# LPC54102_cm4 register map
Vendor: nxp.com; File version: 1.0
LPC54102J256BD64,LPC54102J256UK49,LPC54102J512BD64,LPC54102J512UK49
CPU: CM4 r0p1, little endian, MPU, FPU, VTOR, 3 interrupt priority bits
Registers are 32-bit, read-write, reset 0x0 unless marked. A register's access mark holds for its fields unless they carry their own. Offsets are from the block's base; lines under a group give offsets from that group; [hi:lo] are bit positions; {n}, {i} and the like mark numbered series; 'fields as' and 'values as' point back to an identical list; <NAME> marks a mode.

## Memory map
0x1C000000 GPIO size 0x2488 — LPC5410x General Purpose I/O (GPIO)
0x1C004000 DMA0 size 0x55C — LPC5410x DMA controller
0x1C010000 CRC_ENGINE size 0xC — LPC5410x CRC engine
0x1C018000 SCT0 size 0x540 — SCTimer/PWM (SCT)
0x1C02C000 MAILBOX size 0xFC — LPC5410x Mailbox
0x1C034000 ADC0 size 0x74 — LPC5410x 12-bit ADC controller (ADC)
0x1C038000 VFIFO size 0x211C — System FIFO for Serial Peripherals
0x40000000 SYSCON size 0x2C048 — System configuration
0x40004000 CTIMER2 size 0x78 — LPC5410x Standard counter/timers (CTIMER0 to 4)
0x40008000 CTIMER3 size 0x78 — LPC5410x Standard counter/timers (CTIMER0 to 4)
0x4000C000 CTIMER4 size 0x78 — LPC5410x Standard counter/timers (CTIMER0 to 4)
0x40010000 GINT0 size 0x48 — LPC5410x Group GPIO input interrupt (GINT0/1)
0x40014000 GINT1 size 0x48 — LPC5410x Group GPIO input interrupt (GINT0/1)
0x40018000 PINT size 0x34 — LPC5410x Pin interrupt and pattern match (PINT)
0x4001C000 IOCON size 0x100 — LPC5410x I/O pin configuration (IOCON)
0x40020000 UTICK0 size 0x20 — LPC5410x Micro-tick Timer (UTICK)
0x40038000 WWDT size 0x1C — LPC5410x Windowed Watchdog Timer (WWDT)
0x4003C000 RTC size 0x10 — LPC5410x Real-Time Clock (RTC)
0x40050000 INPUTMUX size 0x168 — LPC5410x Input multiplexing (INPUT MUX)
0x40070000 RIT size 0x20 — Repetitive Interrupt Timer
0x40074000 MRT0 size 0xFC — LPC5410x Multi-Rate Timer (MRT)
0x40080000 ASYNC_SYSCON size 0x34 — LPC5410x Asynchronous system configuration (ASYNC_SYSCON)
0x40084000 USART0 size 0x30 — USART
0x40088000 USART1 size 0x30 — USART
0x4008C000 USART2 size 0x30 — USART
0x40090000 USART3 size 0x30 — USART
0x40094000 I2C0 size 0x84 — I2C-bus interface 0
0x40098000 I2C1 size 0x84 — I2C-bus interface 0
0x4009C000 I2C2 size 0x84 — I2C-bus interface 0
0x400A4000 SPI0 size 0x2C — SPI
0x400A8000 SPI1 size 0x2C — SPI
0x400B4000 CTIMER0 size 0x78 — LPC5410x Standard counter/timers (CTIMER0 to 4)
0x400B8000 CTIMER1 size 0x78 — LPC5410x Standard counter/timers (CTIMER0 to 4)
0xE0000000 ITM size 0x1000 — Instrumentation Trace Macrocell Registers
0xE000E000 SystemControl size 0xD40 — System Control Block
0xE000E010 SysTick size 0x10 — System timer
0xE000E100 NVIC size 0xE04 — Nested Vectored Interrupt Controller

## Interrupts
0 WDT (WWDT)
3 DMA0
4 GINT0
5 PIN_INT0 (PINT)
6 PIN_INT1 (PINT)
7 PIN_INT2 (PINT)
8 PIN_INT3 (PINT)
9 UTICK0
10 MRT0
11 CTIMER0
12 CTIMER1
13 CTIMER2
14 CTIMER3
15 CTIMER4
16 SCT0
17 USART0
18 USART1
19 USART2
20 USART3
21 I2C0
22 I2C1
23 I2C2
24 SPI0
25 SPI1
26 ADC0_SEQA (ADC0)
27 ADC0_SEQB (ADC0)
28 ADC0_THCMP (ADC0)
29 RTC
31 MAILBOX
32 GINT1
33 PIN_INT4 (PINT)
34 PIN_INT5 (PINT)
35 PIN_INT6 (PINT)
36 PIN_INT7 (PINT)
40 RIT

## CRC_ENGINE — LPC5410x CRC engine
Base 0x1C010000
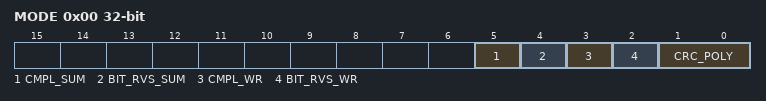
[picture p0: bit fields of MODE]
0x00 MODE — CRC mode register
  [5] CMPL_SUM — CRC sum complement: 1 = 1's complement for CRC_SUM 0 = No 1's complement for CRC_SUM
  [4] BIT_RVS_SUM — CRC sum bit order: 1 = Bit order reverse for CRC_SUM 0 = No bit order reverse for CRC_SUM
  [3] CMPL_WR — Data complement: 1 = 1's complement for CRC_WR_DATA 0 = No 1's complement for CRC_WR_DATA
  [2] BIT_RVS_WR — Data bit order: 1 = Bit order reverse for CRC_WR_DATA (per byte) 0 = No bit order reverse for CRC_WR_DATA (per byte)
  [1:0] CRC_POLY — CRC polynomial: 1X = CRC-32 polynomial 01 = CRC-16 polynomial 00 = CRC-CCITT polynomial
0x04 SEED reset 0xFFFF — CRC seed register
  [31:0] CRC_SEED — A write access to this register will load CRC seed value to CRC_SUM register with selected bit order and 1's complement pre-processes. A write access to this register will overrule the CRC calculation in progresses.
0x08 SUM ro reset 0xFFFF (SUM_WR_DATA view) — CRC checksum register
  [31:0] CRC_SUM — The most recent CRC sum can be read through this register with selected bit order and 1's complement post-processes.
0x08 WR_DATA wo reset not defined (SUM_WR_DATA view) — CRC data register
  [31:0] CRC_WR_DATA — Data written to this register will be taken to perform CRC calculation with selected bit order and 1's complement pre-process. Any write size 8, 16 or 32-bit are allowed and accept back-to-back transactions.

## Licence text in the file
Copyright 2016-2019 NXP All rights reserved. SPDX-License-Identifier: BSD-3-Clause
